AUTOSAR XML (schema 4-0-3)
package /AUTOSAR_ComM/SwComponentTypes
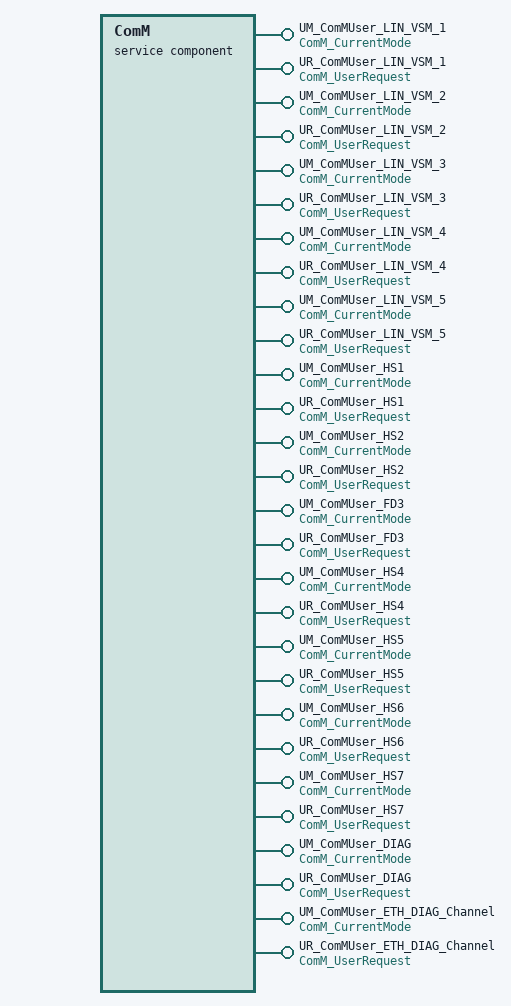
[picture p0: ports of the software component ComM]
  service sw component type ComM
    28 x provide port:
      UM_ComMUser_LIN_VSM_1: mode-switch-sender-com-spec{mode-group=currentMode, queue-length=3}, provided-interface=ComM_CurrentMode
      UR_ComMUser_LIN_VSM_1: provided-interface=ComM_UserRequest
        provided-com-specs:
          operation=RequestComMode, queue-length=1
          operation=GetCurrentComMode, queue-length=1
          operation=GetMaxComMode, queue-length=1
          operation=GetRequestedComMode, queue-length=1
      UM_ComMUser_LIN_VSM_2: mode-switch-sender-com-spec{mode-group=currentMode, queue-length=3}, provided-interface=ComM_CurrentMode
      UR_ComMUser_LIN_VSM_2: provided-interface=ComM_UserRequest
        provided-com-specs:
          operation=RequestComMode, queue-length=1
          operation=GetCurrentComMode, queue-length=1
          operation=GetMaxComMode, queue-length=1
          operation=GetRequestedComMode, queue-length=1
      UM_ComMUser_LIN_VSM_3: mode-switch-sender-com-spec{mode-group=currentMode, queue-length=3}, provided-interface=ComM_CurrentMode
      UR_ComMUser_LIN_VSM_3: provided-interface=ComM_UserRequest
        provided-com-specs:
          operation=RequestComMode, queue-length=1
          operation=GetCurrentComMode, queue-length=1
          operation=GetMaxComMode, queue-length=1
          operation=GetRequestedComMode, queue-length=1
      UM_ComMUser_LIN_VSM_4: mode-switch-sender-com-spec{mode-group=currentMode, queue-length=3}, provided-interface=ComM_CurrentMode
      UR_ComMUser_LIN_VSM_4: provided-interface=ComM_UserRequest
        provided-com-specs:
          operation=RequestComMode, queue-length=1
          operation=GetCurrentComMode, queue-length=1
          operation=GetMaxComMode, queue-length=1
          operation=GetRequestedComMode, queue-length=1
      UM_ComMUser_LIN_VSM_5: mode-switch-sender-com-spec{mode-group=currentMode, queue-length=3}, provided-interface=ComM_CurrentMode
      UR_ComMUser_LIN_VSM_5: provided-interface=ComM_UserRequest
        provided-com-specs:
          operation=RequestComMode, queue-length=1
          operation=GetCurrentComMode, queue-length=1
          operation=GetMaxComMode, queue-length=1
          operation=GetRequestedComMode, queue-length=1
      UM_ComMUser_HS1: mode-switch-sender-com-spec{mode-group=currentMode, queue-length=3}, provided-interface=ComM_CurrentMode
      UR_ComMUser_HS1: provided-interface=ComM_UserRequest
        provided-com-specs:
          operation=RequestComMode, queue-length=1
          operation=GetCurrentComMode, queue-length=1
          operation=GetMaxComMode, queue-length=1
          operation=GetRequestedComMode, queue-length=1
      UM_ComMUser_HS2: mode-switch-sender-com-spec{mode-group=currentMode, queue-length=3}, provided-interface=ComM_CurrentMode
      UR_ComMUser_HS2: provided-interface=ComM_UserRequest
        provided-com-specs:
          operation=RequestComMode, queue-length=1
          operation=GetCurrentComMode, queue-length=1
          operation=GetMaxComMode, queue-length=1
          operation=GetRequestedComMode, queue-length=1
      UM_ComMUser_FD3: mode-switch-sender-com-spec{mode-group=currentMode, queue-length=3}, provided-interface=ComM_CurrentMode
      UR_ComMUser_FD3: provided-interface=ComM_UserRequest
        provided-com-specs:
          operation=RequestComMode, queue-length=1
          operation=GetCurrentComMode, queue-length=1
          operation=GetMaxComMode, queue-length=1
          operation=GetRequestedComMode, queue-length=1
      UM_ComMUser_HS4: mode-switch-sender-com-spec{mode-group=currentMode, queue-length=3}, provided-interface=ComM_CurrentMode
      UR_ComMUser_HS4: provided-interface=ComM_UserRequest
        provided-com-specs:
          operation=RequestComMode, queue-length=1
          operation=GetCurrentComMode, queue-length=1
          operation=GetMaxComMode, queue-length=1
          operation=GetRequestedComMode, queue-length=1
      UM_ComMUser_HS5: mode-switch-sender-com-spec{mode-group=currentMode, queue-length=3}, provided-interface=ComM_CurrentMode
      UR_ComMUser_HS5: provided-interface=ComM_UserRequest
        provided-com-specs:
          operation=RequestComMode, queue-length=1
          operation=GetCurrentComMode, queue-length=1
          operation=GetMaxComMode, queue-length=1
          operation=GetRequestedComMode, queue-length=1
      UM_ComMUser_HS6: mode-switch-sender-com-spec{mode-group=currentMode, queue-length=3}, provided-interface=ComM_CurrentMode
      UR_ComMUser_HS6: provided-interface=ComM_UserRequest
        provided-com-specs:
          operation=RequestComMode, queue-length=1
          operation=GetCurrentComMode, queue-length=1
          operation=GetMaxComMode, queue-length=1
          operation=GetRequestedComMode, queue-length=1
      UM_ComMUser_HS7: mode-switch-sender-com-spec{mode-group=currentMode, queue-length=3}, provided-interface=ComM_CurrentMode
      UR_ComMUser_HS7: provided-interface=ComM_UserRequest
        provided-com-specs:
          operation=RequestComMode, queue-length=1
          operation=GetCurrentComMode, queue-length=1
          operation=GetMaxComMode, queue-length=1
          operation=GetRequestedComMode, queue-length=1
      UM_ComMUser_DIAG: mode-switch-sender-com-spec{mode-group=currentMode, queue-length=3}, provided-interface=ComM_CurrentMode
      UR_ComMUser_DIAG: provided-interface=ComM_UserRequest
        provided-com-specs:
          operation=RequestComMode, queue-length=1
          operation=GetCurrentComMode, queue-length=1
          operation=GetMaxComMode, queue-length=1
          operation=GetRequestedComMode, queue-length=1
      UM_ComMUser_ETH_DIAG_Channel: mode-switch-sender-com-spec{mode-group=currentMode, queue-length=3}, provided-interface=ComM_CurrentMode
      UR_ComMUser_ETH_DIAG_Channel: provided-interface=ComM_UserRequest
        provided-com-specs:
          operation=RequestComMode, queue-length=1
          operation=GetCurrentComMode, queue-length=1
          operation=GetMaxComMode, queue-length=1
          operation=GetRequestedComMode, queue-length=1
    behavior SwcInternalBehavior_0: data-type-mapping=DataTypeMappingSet_0, handle-termination-and-restart=NO-SUPPORT
      56 x operation invoked event:
        EV_RequestComMode_ComMUser_LIN_VSM_1: start-on-event=RE_RequestComMode, operation=UR_ComMUser_LIN_VSM_1.RequestComMode
        EV_GetCurrentComMode_ComMUser_LIN_VSM_1: start-on-event=RE_GetCurrentComMode, operation=UR_ComMUser_LIN_VSM_1.GetCurrentComMode
        EV_GetMaxComMode_ComMUser_LIN_VSM_1: start-on-event=RE_GetMaxComMode, operation=UR_ComMUser_LIN_VSM_1.GetMaxComMode
        EV_GetRequestedComMode_ComMUser_LIN_VSM_1: start-on-event=RE_GetRequestedComMode, operation=UR_ComMUser_LIN_VSM_1.GetRequestedComMode
        EV_RequestComMode_ComMUser_LIN_VSM_2: start-on-event=RE_RequestComMode, operation=UR_ComMUser_LIN_VSM_2.RequestComMode
        EV_GetCurrentComMode_ComMUser_LIN_VSM_2: start-on-event=RE_GetCurrentComMode, operation=UR_ComMUser_LIN_VSM_2.GetCurrentComMode
        EV_GetMaxComMode_ComMUser_LIN_VSM_2: start-on-event=RE_GetMaxComMode, operation=UR_ComMUser_LIN_VSM_2.GetMaxComMode
        EV_GetRequestedComMode_ComMUser_LIN_VSM_2: start-on-event=RE_GetRequestedComMode, operation=UR_ComMUser_LIN_VSM_2.GetRequestedComMode
        EV_RequestComMode_ComMUser_LIN_VSM_3: start-on-event=RE_RequestComMode, operation=UR_ComMUser_LIN_VSM_3.RequestComMode
        EV_GetCurrentComMode_ComMUser_LIN_VSM_3: start-on-event=RE_GetCurrentComMode, operation=UR_ComMUser_LIN_VSM_3.GetCurrentComMode
        EV_GetMaxComMode_ComMUser_LIN_VSM_3: start-on-event=RE_GetMaxComMode, operation=UR_ComMUser_LIN_VSM_3.GetMaxComMode
        EV_GetRequestedComMode_ComMUser_LIN_VSM_3: start-on-event=RE_GetRequestedComMode, operation=UR_ComMUser_LIN_VSM_3.GetRequestedComMode
        EV_RequestComMode_ComMUser_LIN_VSM_4: start-on-event=RE_RequestComMode, operation=UR_ComMUser_LIN_VSM_4.RequestComMode
        EV_GetCurrentComMode_ComMUser_LIN_VSM_4: start-on-event=RE_GetCurrentComMode, operation=UR_ComMUser_LIN_VSM_4.GetCurrentComMode
        EV_GetMaxComMode_ComMUser_LIN_VSM_4: start-on-event=RE_GetMaxComMode, operation=UR_ComMUser_LIN_VSM_4.GetMaxComMode
        EV_GetRequestedComMode_ComMUser_LIN_VSM_4: start-on-event=RE_GetRequestedComMode, operation=UR_ComMUser_LIN_VSM_4.GetRequestedComMode
        EV_RequestComMode_ComMUser_LIN_VSM_5: start-on-event=RE_RequestComMode, operation=UR_ComMUser_LIN_VSM_5.RequestComMode
        EV_GetCurrentComMode_ComMUser_LIN_VSM_5: start-on-event=RE_GetCurrentComMode, operation=UR_ComMUser_LIN_VSM_5.GetCurrentComMode
        EV_GetMaxComMode_ComMUser_LIN_VSM_5: start-on-event=RE_GetMaxComMode, operation=UR_ComMUser_LIN_VSM_5.GetMaxComMode
        EV_GetRequestedComMode_ComMUser_LIN_VSM_5: start-on-event=RE_GetRequestedComMode, operation=UR_ComMUser_LIN_VSM_5.GetRequestedComMode
        EV_RequestComMode_ComMUser_HS1: start-on-event=RE_RequestComMode, operation=UR_ComMUser_HS1.RequestComMode
        EV_GetCurrentComMode_ComMUser_HS1: start-on-event=RE_GetCurrentComMode, operation=UR_ComMUser_HS1.GetCurrentComMode
        EV_GetMaxComMode_ComMUser_HS1: start-on-event=RE_GetMaxComMode, operation=UR_ComMUser_HS1.GetMaxComMode
        EV_GetRequestedComMode_ComMUser_HS1: start-on-event=RE_GetRequestedComMode, operation=UR_ComMUser_HS1.GetRequestedComMode
        EV_RequestComMode_ComMUser_HS2: start-on-event=RE_RequestComMode, operation=UR_ComMUser_HS2.RequestComMode
        EV_GetCurrentComMode_ComMUser_HS2: start-on-event=RE_GetCurrentComMode, operation=UR_ComMUser_HS2.GetCurrentComMode
        EV_GetMaxComMode_ComMUser_HS2: start-on-event=RE_GetMaxComMode, operation=UR_ComMUser_HS2.GetMaxComMode
        EV_GetRequestedComMode_ComMUser_HS2: start-on-event=RE_GetRequestedComMode, operation=UR_ComMUser_HS2.GetRequestedComMode
        EV_RequestComMode_ComMUser_FD3: start-on-event=RE_RequestComMode, operation=UR_ComMUser_FD3.RequestComMode
        EV_GetCurrentComMode_ComMUser_FD3: start-on-event=RE_GetCurrentComMode, operation=UR_ComMUser_FD3.GetCurrentComMode
        EV_GetMaxComMode_ComMUser_FD3: start-on-event=RE_GetMaxComMode, operation=UR_ComMUser_FD3.GetMaxComMode
        EV_GetRequestedComMode_ComMUser_FD3: start-on-event=RE_GetRequestedComMode, operation=UR_ComMUser_FD3.GetRequestedComMode
        EV_RequestComMode_ComMUser_HS4: start-on-event=RE_RequestComMode, operation=UR_ComMUser_HS4.RequestComMode
        EV_GetCurrentComMode_ComMUser_HS4: start-on-event=RE_GetCurrentComMode, operation=UR_ComMUser_HS4.GetCurrentComMode
        EV_GetMaxComMode_ComMUser_HS4: start-on-event=RE_GetMaxComMode, operation=UR_ComMUser_HS4.GetMaxComMode
        EV_GetRequestedComMode_ComMUser_HS4: start-on-event=RE_GetRequestedComMode, operation=UR_ComMUser_HS4.GetRequestedComMode
        EV_RequestComMode_ComMUser_HS5: start-on-event=RE_RequestComMode, operation=UR_ComMUser_HS5.RequestComMode
        EV_GetCurrentComMode_ComMUser_HS5: start-on-event=RE_GetCurrentComMode, operation=UR_ComMUser_HS5.GetCurrentComMode
        EV_GetMaxComMode_ComMUser_HS5: start-on-event=RE_GetMaxComMode, operation=UR_ComMUser_HS5.GetMaxComMode
        EV_GetRequestedComMode_ComMUser_HS5: start-on-event=RE_GetRequestedComMode, operation=UR_ComMUser_HS5.GetRequestedComMode
        EV_RequestComMode_ComMUser_HS6: start-on-event=RE_RequestComMode, operation=UR_ComMUser_HS6.RequestComMode
        EV_GetCurrentComMode_ComMUser_HS6: start-on-event=RE_GetCurrentComMode, operation=UR_ComMUser_HS6.GetCurrentComMode
        EV_GetMaxComMode_ComMUser_HS6: start-on-event=RE_GetMaxComMode, operation=UR_ComMUser_HS6.GetMaxComMode
        EV_GetRequestedComMode_ComMUser_HS6: start-on-event=RE_GetRequestedComMode, operation=UR_ComMUser_HS6.GetRequestedComMode
        EV_RequestComMode_ComMUser_HS7: start-on-event=RE_RequestComMode, operation=UR_ComMUser_HS7.RequestComMode
        EV_GetCurrentComMode_ComMUser_HS7: start-on-event=RE_GetCurrentComMode, operation=UR_ComMUser_HS7.GetCurrentComMode
        EV_GetMaxComMode_ComMUser_HS7: start-on-event=RE_GetMaxComMode, operation=UR_ComMUser_HS7.GetMaxComMode
        EV_GetRequestedComMode_ComMUser_HS7: start-on-event=RE_GetRequestedComMode, operation=UR_ComMUser_HS7.GetRequestedComMode
        EV_RequestComMode_ComMUser_DIAG: start-on-event=RE_RequestComMode, operation=UR_ComMUser_DIAG.RequestComMode
        EV_GetCurrentComMode_ComMUser_DIAG: start-on-event=RE_GetCurrentComMode, operation=UR_ComMUser_DIAG.GetCurrentComMode
        EV_GetMaxComMode_ComMUser_DIAG: start-on-event=RE_GetMaxComMode, operation=UR_ComMUser_DIAG.GetMaxComMode
        EV_GetRequestedComMode_ComMUser_DIAG: start-on-event=RE_GetRequestedComMode, operation=UR_ComMUser_DIAG.GetRequestedComMode
        EV_RequestComMode_ComMUser_ETH_DIAG_Channel: start-on-event=RE_RequestComMode, operation=UR_ComMUser_ETH_DIAG_Channel.RequestComMode
        EV_GetCurrentComMode_ComMUser_ETH_DIAG_Channel: start-on-event=RE_GetCurrentComMode, operation=UR_ComMUser_ETH_DIAG_Channel.GetCurrentComMode
        EV_GetMaxComMode_ComMUser_ETH_DIAG_Channel: start-on-event=RE_GetMaxComMode, operation=UR_ComMUser_ETH_DIAG_Channel.GetMaxComMode
        EV_GetRequestedComMode_ComMUser_ETH_DIAG_Channel: start-on-event=RE_GetRequestedComMode, operation=UR_ComMUser_ETH_DIAG_Channel.GetRequestedComMode
      port-api-options:
        enable-take-address=true, indirect-api=false, port=UM_ComMUser_LIN_VSM_1
        {enable-take-address=false, indirect-api=false, port-defined-argument-value{value=0, value-type=ComM_UserHandleType}, port=UR_ComMUser_LIN_VSM_1}
        enable-take-address=true, indirect-api=false, port=UM_ComMUser_LIN_VSM_2
        {enable-take-address=false, indirect-api=false, port-defined-argument-value{value=1, value-type=ComM_UserHandleType}, port=UR_ComMUser_LIN_VSM_2}
        enable-take-address=true, indirect-api=false, port=UM_ComMUser_LIN_VSM_3
        {enable-take-address=false, indirect-api=false, port-defined-argument-value{value=2, value-type=ComM_UserHandleType}, port=UR_ComMUser_LIN_VSM_3}
        enable-take-address=true, indirect-api=false, port=UM_ComMUser_LIN_VSM_4
        {enable-take-address=false, indirect-api=false, port-defined-argument-value{value=3, value-type=ComM_UserHandleType}, port=UR_ComMUser_LIN_VSM_4}
        enable-take-address=true, indirect-api=false, port=UM_ComMUser_LIN_VSM_5
        {enable-take-address=false, indirect-api=false, port-defined-argument-value{value=4, value-type=ComM_UserHandleType}, port=UR_ComMUser_LIN_VSM_5}
        enable-take-address=true, indirect-api=false, port=UM_ComMUser_HS1
        {enable-take-address=false, indirect-api=false, port-defined-argument-value{value=5, value-type=ComM_UserHandleType}, port=UR_ComMUser_HS1}
        enable-take-address=true, indirect-api=false, port=UM_ComMUser_HS2
        {enable-take-address=false, indirect-api=false, port-defined-argument-value{value=6, value-type=ComM_UserHandleType}, port=UR_ComMUser_HS2}
        enable-take-address=true, indirect-api=false, port=UM_ComMUser_FD3
        {enable-take-address=false, indirect-api=false, port-defined-argument-value{value=7, value-type=ComM_UserHandleType}, port=UR_ComMUser_FD3}
        enable-take-address=true, indirect-api=false, port=UM_ComMUser_HS4
        {enable-take-address=false, indirect-api=false, port-defined-argument-value{value=8, value-type=ComM_UserHandleType}, port=UR_ComMUser_HS4}
        enable-take-address=true, indirect-api=false, port=UM_ComMUser_HS5
        {enable-take-address=false, indirect-api=false, port-defined-argument-value{value=9, value-type=ComM_UserHandleType}, port=UR_ComMUser_HS5}
        enable-take-address=true, indirect-api=false, port=UM_ComMUser_HS6
        {enable-take-address=false, indirect-api=false, port-defined-argument-value{value=10, value-type=ComM_UserHandleType}, port=UR_ComMUser_HS6}
        enable-take-address=true, indirect-api=false, port=UM_ComMUser_HS7
        {enable-take-address=false, indirect-api=false, port-defined-argument-value{value=11, value-type=ComM_UserHandleType}, port=UR_ComMUser_HS7}
        enable-take-address=true, indirect-api=false, port=UM_ComMUser_DIAG
        {enable-take-address=false, indirect-api=false, port-defined-argument-value{value=12, value-type=ComM_UserHandleType}, port=UR_ComMUser_DIAG}
        enable-take-address=true, indirect-api=false, port=UM_ComMUser_ETH_DIAG_Channel
        {enable-take-address=false, indirect-api=false, port-defined-argument-value{value=13, value-type=ComM_UserHandleType}, port=UR_ComMUser_ETH_DIAG_Channel}
      18 x runnable:
        RE_RequestComMode: arguments=[symbol=pdav0, symbol=ComMode], can-be-invoked-concurrently=true, symbol=ComM_Rte_RequestComMode
        RE_GetCurrentComMode: arguments=[symbol=pdav0, symbol=ComMode], can-be-invoked-concurrently=true, symbol=ComM_Rte_GetCurrentComMode
        RE_GetMaxComMode: arguments=[symbol=pdav0, symbol=ComMode], can-be-invoked-concurrently=true, symbol=ComM_Rte_GetMaxComMode
        RE_GetRequestedComMode: arguments=[symbol=pdav0, symbol=ComMode], can-be-invoked-concurrently=true, symbol=ComM_Rte_GetRequestedComMode
        RE_Main_0: symbol=ComM_MainFunction_0
          mode switch point MSP_ComMUser_DIAG: mode-group=UM_ComMUser_DIAG.currentMode
        RE_Main_1: symbol=ComM_MainFunction_1
          mode switch point MSP_ComMUser_FD3: mode-group=UM_ComMUser_FD3.currentMode
        RE_Main_2: symbol=ComM_MainFunction_2
          mode switch point MSP_ComMUser_HS1: mode-group=UM_ComMUser_HS1.currentMode
        RE_Main_3: symbol=ComM_MainFunction_3
          mode switch point MSP_ComMUser_HS2: mode-group=UM_ComMUser_HS2.currentMode
        RE_Main_4: symbol=ComM_MainFunction_4
          mode switch point MSP_ComMUser_HS4: mode-group=UM_ComMUser_HS4.currentMode
        RE_Main_5: symbol=ComM_MainFunction_5
          mode switch point MSP_ComMUser_HS5: mode-group=UM_ComMUser_HS5.currentMode
        RE_Main_6: symbol=ComM_MainFunction_6
          mode switch point MSP_ComMUser_HS6: mode-group=UM_ComMUser_HS6.currentMode
        RE_Main_7: symbol=ComM_MainFunction_7
          mode switch point MSP_ComMUser_HS7: mode-group=UM_ComMUser_HS7.currentMode
        RE_Main_8: symbol=ComM_MainFunction_8
          mode switch point MSP_ComMUser_LIN_VSM_1: mode-group=UM_ComMUser_LIN_VSM_1.currentMode
        RE_Main_9: symbol=ComM_MainFunction_9
          mode switch point MSP_ComMUser_LIN_VSM_2: mode-group=UM_ComMUser_LIN_VSM_2.currentMode
        RE_Main_10: symbol=ComM_MainFunction_10
          mode switch point MSP_ComMUser_LIN_VSM_3: mode-group=UM_ComMUser_LIN_VSM_3.currentMode
        RE_Main_11: symbol=ComM_MainFunction_11
          mode switch point MSP_ComMUser_LIN_VSM_4: mode-group=UM_ComMUser_LIN_VSM_4.currentMode
        RE_Main_12: symbol=ComM_MainFunction_12
          mode switch point MSP_ComMUser_LIN_VSM_5: mode-group=UM_ComMUser_LIN_VSM_5.currentMode
        RE_Main_13: symbol=ComM_MainFunction_13
          mode switch point MSP_ComMUser_ETH_DIAG_Channel: mode-group=UM_ComMUser_ETH_DIAG_Channel.currentMode
package /EB_ComM_TxDxM5I17R0/SwcImplementations
  swc implementation SwcImplementation_0: programming-language=C, sw-version=5.17.0, vendor-id=1, behavior=SwcInternalBehavior_0
    code-descriptors:
      code ComMCode: artifact-descriptors=autosar-engineering-object={short-label=EngObject, category=SWSRC}
    resource consumption Resources
